# STM32F071xB register map
File version: 1.0
Registers are 32-bit, access not given, reset 0x0 unless marked. A register's access mark holds for its fields unless they carry their own. Offsets are from the block's base; [hi:lo] are bit positions; {n}, {i} and the like mark numbered series; 'fields as' and 'values as' point back to an identical list.

## PWR
Base 0x40007000
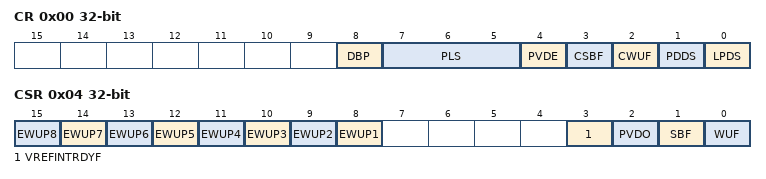
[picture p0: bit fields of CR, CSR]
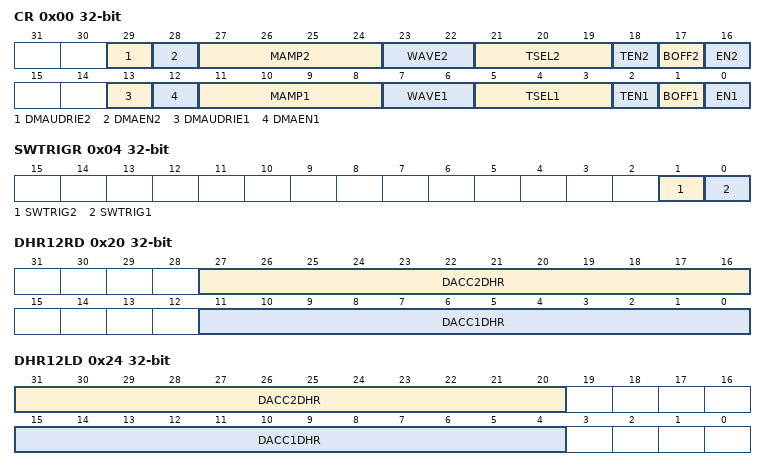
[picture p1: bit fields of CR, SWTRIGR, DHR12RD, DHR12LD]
0x00 CR
  [8] DBP, [7:5] PLS, [4] PVDE, [3] CSBF, [2] CWUF, [1] PDDS, [0] LPDS
0x04 CSR
  [n+7] EWUP{n} (n=1..8), [3] VREFINTRDYF, [2] PVDO, [1] SBF, [0] WUF

## DAC1
Base 0x40007400
0x00 CR
  [29] DMAUDRIE2, [28] DMAEN2, [27:24] MAMP2, [23:22] WAVE2, [21:19] TSEL2, [18] TEN2, [17] BOFF2, [16] EN2, [13] DMAUDRIE1, [12] DMAEN1, [11:8] MAMP1, [7:6] WAVE1, [5:3] TSEL1, [2] TEN1, [1] BOFF1, [0] EN1
0x04 SWTRIGR
  [1] SWTRIG2, [0] SWTRIG1
0x08 DHR12R1
  [11:0] DACC1DHR
0x0C DHR12L1
  [15:4] DACC1DHR
0x10 DHR8R1
  [7:0] DACC1DHR
0x14 DHR12R2
  [11:0] DACC2DHR
0x18 DHR12L2
  [15:4] DACC2DHR
0x1C DHR8R2
  [7:0] DACC2DHR
0x20 DHR12RD
  [27:16] DACC2DHR, [11:0] DACC1DHR
0x24 DHR12LD
  [31:20] DACC2DHR, [15:4] DACC1DHR
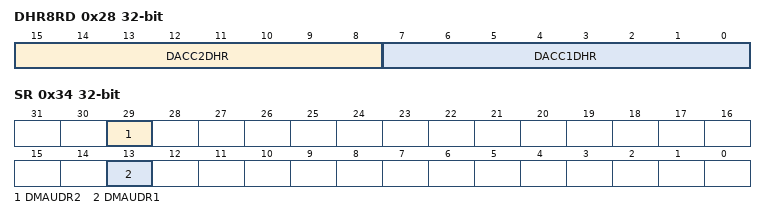
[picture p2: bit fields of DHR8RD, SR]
0x28 DHR8RD
  [15:8] DACC2DHR, [7:0] DACC1DHR
0x2C DOR1
  [11:0] DACC1DOR
0x30 DOR2
  [11:0] DACC2DOR
0x34 SR
  [29] DMAUDR2, [13] DMAUDR1

## CEC
Base 0x40007800
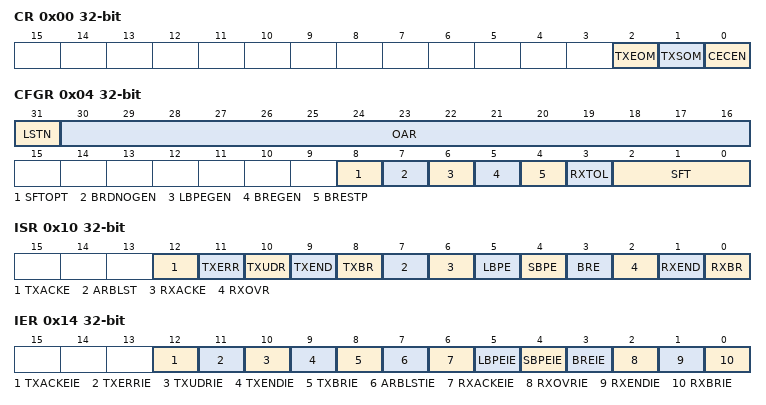
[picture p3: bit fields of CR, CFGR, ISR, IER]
0x00 CR
  [2] TXEOM, [1] TXSOM, [0] CECEN
0x04 CFGR
  [31] LSTN, [30:16] OAR, [8] SFTOPT, [7] BRDNOGEN, [6] LBPEGEN, [5] BREGEN, [4] BRESTP, [3] RXTOL, [2:0] SFT
0x08 TXDR
  [7:0] TXD
0x0C RXDR
0x10 ISR
  [12] TXACKE, [11] TXERR, [10] TXUDR, [9] TXEND, [8] TXBR, [7] ARBLST, [6] RXACKE, [5] LBPE, [4] SBPE, [3] BRE, [2] RXOVR, [1] RXEND, [0] RXBR
0x14 IER
  [12] TXACKEIE, [11] TXERRIE, [10] TXUDRIE, [9] TXENDIE, [8] TXBRIE, [7] ARBLSTIE, [6] RXACKEIE, [5] LBPEIE, [4] SBPEIE, [3] BREIE, [2] RXOVRIE, [1] RXENDIE, [0] RXBRIE

## SYSCFG
Base 0x40010000
0x00 CFGR1
  [30] TIM3_DMA_RMP, [29] TIM2_DMA_RMP, [28] TIM1_DMA_RMP, [27] I2C1_DMA_RMP, [26] USART3_DMA_RMP, [25] USART2_DMA_RMP, [24] SPI2_DMA_RMP, [21] I2C_FMP_I2C2, [20] I2C_FMP_I2C1, [n+10] I2C_FMP_PB{n} (n=6..9), [14] TIM17_DMA_RMP2, [13] TIM16_DMA_RMP2, [12] TIM17_DMA_RMP, [11] TIM16_DMA_RMP, [10] USART1RX_DMA_RMP, [9] USART1TX_DMA_RMP, [30:8] DMA_RMP, [1:0] MEM_MODE
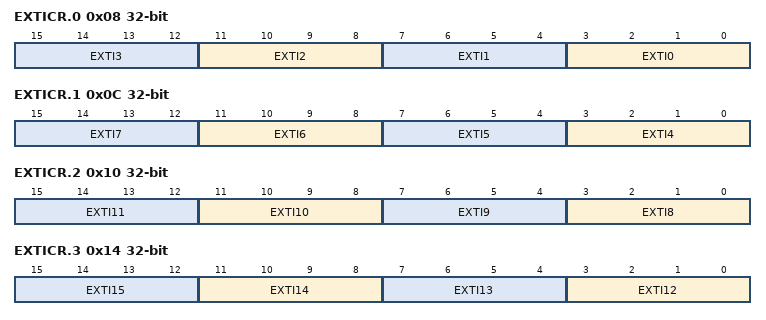
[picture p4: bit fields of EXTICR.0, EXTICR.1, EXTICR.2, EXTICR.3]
0x08 EXTICR.0
  [4n+3:4n] EXTI{n} (n=0..3)
0x0C EXTICR.1
  [4n-13:4n-16] EXTI{n} (n=4..7)
0x10 EXTICR.2
  [4n-29:4n-32] EXTI{n} (n=8..11)
0x14 EXTICR.3
  [4n-45:4n-48] EXTI{n} (n=12..15)
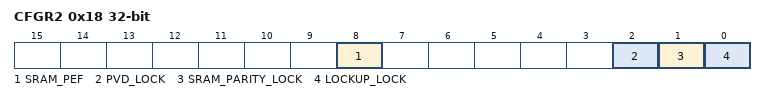
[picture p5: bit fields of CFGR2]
0x18 CFGR2
  [8] SRAM_PEF, [2] PVD_LOCK, [1] SRAM_PARITY_LOCK, [0] LOCKUP_LOCK

## COMP1
Base 0x4001001C
0x00 CSR 16-bit
  [31] COMP2LOCK, [30] COMP2OUT, [29:28] COMP2HYST, [27] COMP2POL, [26:24] COMP2OUTSEL, [23] WNDWEN, [22:20] COMP2INSEL, [19:18] COMP2MODE, [16] COMP2EN, [15] COMPxLOCK, [14] COMPxOUT, [13:12] COMPxHYST, [11] COMPxPOL, [10:8] COMPxOUTSEL, [6:4] COMPxINSEL, [3:2] COMPxMODE, [1] COMP1SW1, [0] COMPxEN

## COMP12_COMMON
Base 0x4001001C
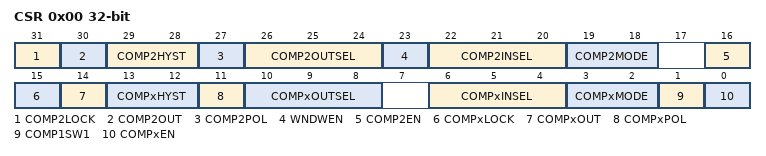
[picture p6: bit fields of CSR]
0x00 CSR
  [31] COMP2LOCK, [30] COMP2OUT, [29:28] COMP2HYST, [27] COMP2POL, [26:24] COMP2OUTSEL, [23] WNDWEN, [22:20] COMP2INSEL, [19:18] COMP2MODE, [16] COMP2EN, [15] COMPxLOCK, [14] COMPxOUT, [13:12] COMPxHYST, [11] COMPxPOL, [10:8] COMPxOUTSEL, [6:4] COMPxINSEL, [3:2] COMPxMODE, [1] COMP1SW1, [0] COMPxEN

## COMP2
Base 0x4001001E
0x00 CSR 16-bit
  [31] COMP2LOCK, [30] COMP2OUT, [29:28] COMP2HYST, [27] COMP2POL, [26:24] COMP2OUTSEL, [23] WNDWEN, [22:20] COMP2INSEL, [19:18] COMP2MODE, [16] COMP2EN, [15] COMPxLOCK, [14] COMPxOUT, [13:12] COMPxHYST, [11] COMPxPOL, [10:8] COMPxOUTSEL, [6:4] COMPxINSEL, [3:2] COMPxMODE, [1] COMP1SW1, [0] COMPxEN

## EXTI
Base 0x40010400
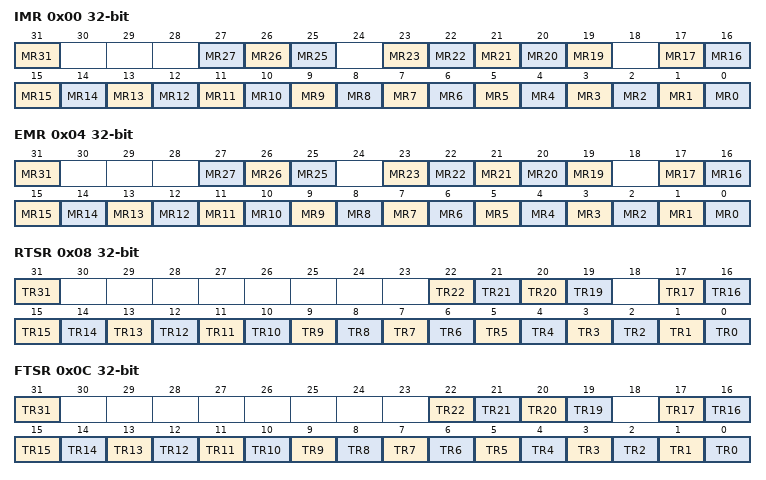
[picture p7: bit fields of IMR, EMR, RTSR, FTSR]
0x00 IMR
  [31] MR31, [27] MR27, [26] MR26, [25] MR25, [n] MR{n} (n=19..23), [n] MR{n} (n=0..17)
0x04 EMR
  fields as IMR
0x08 RTSR
  [31] TR31, [n] TR{n} (n=19..22), [n] TR{n} (n=0..17)
0x0C FTSR
  [31] TR31, [n] TR{n} (n=19..22), [n] TR{n} (n=0..17)
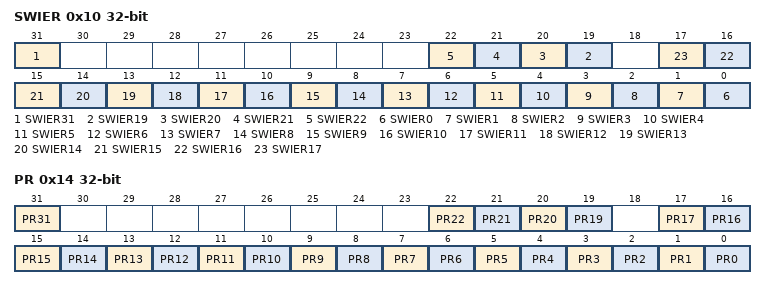
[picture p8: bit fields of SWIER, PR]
0x10 SWIER
  [31] SWIER31, [n] SWIER{n} (n=19..22), [n] SWIER{n} (n=0..17)
0x14 PR
  [31] PR31, [n] PR{n} (n=19..22), [n] PR{n} (n=0..17)

## ADC1
Base 0x40012400
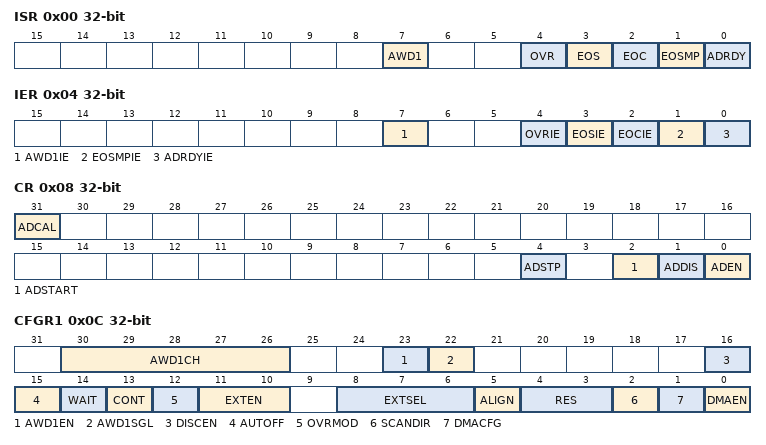
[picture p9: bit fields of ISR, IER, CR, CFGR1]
0x00 ISR
  [7] AWD1, [4] OVR, [3] EOS, [2] EOC, [1] EOSMP, [0] ADRDY
0x04 IER
  [7] AWD1IE, [4] OVRIE, [3] EOSIE, [2] EOCIE, [1] EOSMPIE, [0] ADRDYIE
0x08 CR
  [31] ADCAL, [4] ADSTP, [2] ADSTART, [1] ADDIS, [0] ADEN
0x0C CFGR1
  [30:26] AWD1CH, [23] AWD1EN, [22] AWD1SGL, [16] DISCEN, [15] AUTOFF, [14] WAIT, [13] CONT, [12] OVRMOD, [11:10] EXTEN, [8:6] EXTSEL, [5] ALIGN, [4:3] RES, [2] SCANDIR, [1] DMACFG, [0] DMAEN
0x10 CFGR2
  [31:30] CKMODE
0x14 SMPR
  [2:0] SMP
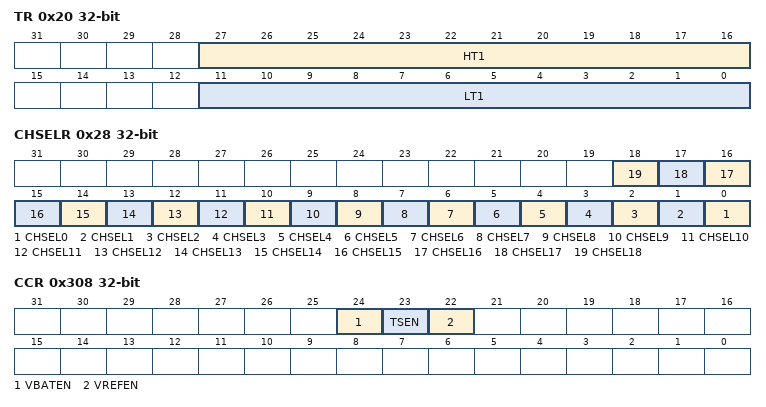
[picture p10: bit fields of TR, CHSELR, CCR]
0x20 TR
  [27:16] HT1, [11:0] LT1
0x28 CHSELR
  [n] CHSEL{n} (n=0..18)
0x40 DR
  [15:0] DATA
0x308 CCR
  [24] VBATEN, [23] TSEN, [22] VREFEN
